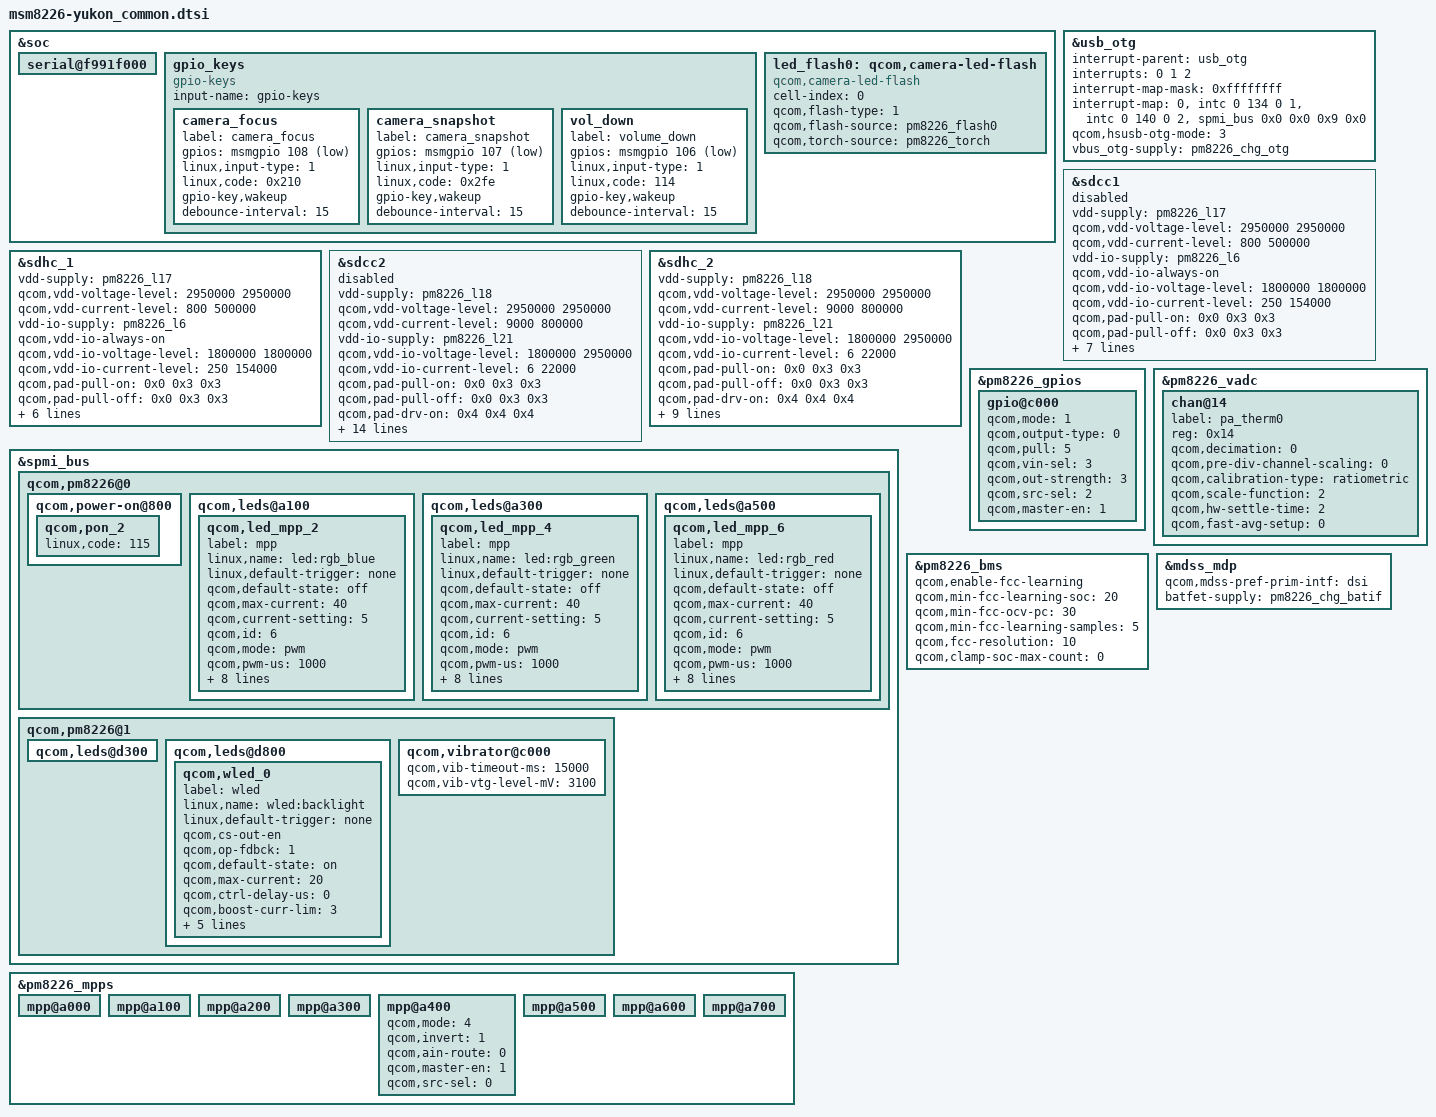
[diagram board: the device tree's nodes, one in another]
/* Copyright (c) 2012-2013, The Linux Foundation. All rights reserved.
 * Copyright (c) 2013 Sony Mobile Communications AB.
 *
 * This program is free software; you can redistribute it and/or modify
 * it under the terms of the GNU General Public License version 2 and
 * only version 2 as published by the Free Software Foundation.
 *
 * This program is distributed in the hope that it will be useful,
 * but WITHOUT ANY WARRANTY; without even the implied warranty of
 * MERCHANTABILITY or FITNESS FOR A PARTICULAR PURPOSE.  See the
 * GNU General Public License for more details.
 */

&soc {
	serial@f991f000 {
		status = "ok";
	};

	gpio_keys {
		compatible = "gpio-keys";
		input-name = "gpio-keys";
		camera_focus {
			label = "camera_focus";
			gpios = <&msmgpio 108 0x1>;
			linux,input-type = <1>;
			linux,code = <0x210>;
			gpio-key,wakeup;
			debounce-interval = <15>;
		};

		camera_snapshot {
			label = "camera_snapshot";
			gpios = <&msmgpio 107 0x1>;
			linux,input-type = <1>;
			linux,code = <0x2fe>;
			gpio-key,wakeup;
			debounce-interval = <15>;
		};

		vol_down {
			label = "volume_down";
			gpios = <&msmgpio 106 0x1>;
			linux,input-type = <1>;
			linux,code = <114>;
			gpio-key,wakeup;
			debounce-interval = <15>;
		};
	};

       led_flash0: qcom,camera-led-flash {
               cell-index = <0>;
               compatible = "qcom,camera-led-flash";
               qcom,flash-type = <1>;
               qcom,flash-source = <&pm8226_flash0>;
               qcom,torch-source = <&pm8226_torch>;
       };

};

&usb_otg {
	#address-cells = <0>;
	interrupt-parent = <&usb_otg>;
	interrupts = <0 1 2>;
	#interrupt-cells = <1>;
	interrupt-map-mask = <0xffffffff>;
	interrupt-map = <0 &intc 0 134 0
			1 &intc 0 140 0
			2 &spmi_bus 0x0 0x0 0x9 0x0>;
	interrupt-names = "core_irq", "async_irq", "pmic_id_irq";

	qcom,hsusb-otg-mode = <3>;
	vbus_otg-supply = <&pm8226_chg_otg>;
};

&sdcc1 {
	vdd-supply = <&pm8226_l17>;
	qcom,vdd-voltage-level = <2950000 2950000>;
	qcom,vdd-current-level = <800 500000>;

	vdd-io-supply = <&pm8226_l6>;
	qcom,vdd-io-always-on;
	qcom,vdd-io-voltage-level = <1800000 1800000>;
	qcom,vdd-io-current-level = <250 154000>;

	qcom,pad-pull-on = <0x0 0x3 0x3>; /* no-pull, pull-up, pull-up */
	qcom,pad-pull-off = <0x0 0x3 0x3>; /* no-pull, pull-up, pull-up */
	qcom,pad-drv-on = <0x4 0x4 0x4>; /* 10mA, 10mA, 10mA */
	qcom,pad-drv-off = <0x0 0x0 0x0>; /* 2mA, 2mA, 2mA */

	qcom,clk-rates = <400000 25000000 50000000 100000000 200000000>;
	qcom,sup-voltages = <2950 2950>;

	qcom,bus-speed-mode = "HS200_1p8v", "DDR_1p8v";
	qcom,nonremovable;

	status = "disabled";
};

&sdhc_1 {
	vdd-supply = <&pm8226_l17>;
	qcom,vdd-voltage-level = <2950000 2950000>;
	qcom,vdd-current-level = <800 500000>;

	vdd-io-supply = <&pm8226_l6>;
	qcom,vdd-io-always-on;
	qcom,vdd-io-voltage-level = <1800000 1800000>;
	qcom,vdd-io-current-level = <250 154000>;

	qcom,pad-pull-on = <0x0 0x3 0x3>; /* no-pull, pull-up, pull-up */
	qcom,pad-pull-off = <0x0 0x3 0x3>; /* no-pull, pull-up, pull-up */
	qcom,pad-drv-on = <0x4 0x4 0x4>; /* 10mA, 10mA, 10mA */
	qcom,pad-drv-off = <0x0 0x0 0x0>; /* 2mA, 2mA, 2mA */

	qcom,clk-rates = <400000 25000000 50000000 100000000 200000000>;
	qcom,bus-speed-mode = "HS200_1p8v", "DDR_1p8v";
	qcom,nonremovable;

	status = "ok";
};

&sdcc2 {
	vdd-supply = <&pm8226_l18>;
	qcom,vdd-voltage-level = <2950000 2950000>;
	qcom,vdd-current-level = <9000 800000>;

	vdd-io-supply = <&pm8226_l21>;
	qcom,vdd-io-voltage-level = <1800000 2950000>;
	qcom,vdd-io-current-level = <6 22000>;

	qcom,pad-pull-on = <0x0 0x3 0x3>; /* no-pull, pull-up, pull-up */
	qcom,pad-pull-off = <0x0 0x3 0x3>; /* no-pull, pull-up, pull-up */
	qcom,pad-drv-on = <0x4 0x4 0x4>; /* 10mA, 10mA, 10mA */
	qcom,pad-drv-off = <0x0 0x0 0x0>; /* 2mA, 2mA, 2mA */

	qcom,clk-rates = <400000 25000000 50000000 100000000 200000000>;
	qcom,sup-voltages = <2950 2950>;

	qcom,xpc;
	qcom,bus-speed-mode = "SDR12", "SDR25", "SDR50", "DDR50", "SDR104";
	qcom,current-limit = <600>; #address-cells = <0>; interrupt-parent = <&sdcc2>;
	interrupts = <0 1 2>;
	#interrupt-cells = <1>;
	interrupt-map-mask = <0xffffffff>;
	interrupt-map = <0 &intc 0 125 0
			1 &intc 0 220 0
			2 &msmgpio 38 0x3>;
	interrupt-names = "core_irq", "bam_irq", "status_irq";
	cd-gpios = <&msmgpio 38 0x1>;

	status = "disabled";
};

&sdhc_2 {
	vdd-supply = <&pm8226_l18>;
	qcom,vdd-voltage-level = <2950000 2950000>;
	qcom,vdd-current-level = <9000 800000>;

	vdd-io-supply = <&pm8226_l21>;
	qcom,vdd-io-voltage-level = <1800000 2950000>;
	qcom,vdd-io-current-level = <6 22000>;

	qcom,pad-pull-on = <0x0 0x3 0x3>; /* no-pull, pull-up, pull-up */
	qcom,pad-pull-off = <0x0 0x3 0x3>; /* no-pull, pull-up, pull-up */
	qcom,pad-drv-on = <0x4 0x4 0x4>; /* 10mA, 10mA, 10mA */
	qcom,pad-drv-off = <0x0 0x0 0x0>; /* 2mA, 2mA, 2mA */

	qcom,clk-rates = <400000 25000000 50000000 100000000 200000000>;

	#address-cells = <0>;
	interrupt-parent = <&sdhc_2>;
	interrupts = <0 1 2>;
	#interrupt-cells = <1>;
	interrupt-map-mask = <0xffffffff>;
	interrupt-map = <0 &intc 0 125 0
			1 &intc 0 221 0
			2 &msmgpio 38 0x3>;
	interrupt-names = "hc_irq", "pwr_irq", "status_irq";
	cd-gpios = <&msmgpio 38 0x1>;

	status = "ok";
};

&spmi_bus {
	qcom,pm8226@0 {
		qcom,power-on@800 {
			qcom,pon_2 {
				linux,code = <115>;
			};
		};

		qcom,leds@a100 {
			status = "okay";
			qcom,led_mpp_2 {
				label = "mpp";
				linux,name = "led:rgb_blue";
				linux,default-trigger = "none";
				qcom,default-state = "off";
				qcom,max-current = <40>;
				qcom,current-setting = <5>;
				qcom,id = <6>;
				qcom,mode = "pwm";
				qcom,pwm-us = <1000>;
				qcom,source-sel = <14>;
				qcom,mode-ctrl = <0x60>;
				qcom,pwm-channel = <3>;
				qcom,start-idx = <1>;
				qcom,ramp-step-ms = <120>;
				qcom,duty-pcts = [00 00 00 00 00
						00 00 00 00 00
						50 00 00 00 00
						00 00 00 00 00
						00];
				qcom,use-blink;
			};
		};

		qcom,leds@a300 {
			status = "okay";
			qcom,led_mpp_4 {
				label = "mpp";
				linux,name = "led:rgb_green";
				linux,default-trigger = "none";
				qcom,default-state = "off";
				qcom,max-current = <40>;
				qcom,current-setting = <5>;
				qcom,id = <6>;
				qcom,mode = "pwm";
				qcom,pwm-us = <1000>;
				qcom,source-sel = <8>;
				qcom,mode-ctrl = <0x60>;
				qcom,pwm-channel = <0>;
				qcom,start-idx = <1>;
				qcom,ramp-step-ms = <120>;
				qcom,duty-pcts = [00 00 00 00 00
						00 00 00 00 00
						50 00 00 00 00
						00 00 00 00 00
						00];
				qcom,use-blink;
			};
		};

		qcom,leds@a500 {
			status = "okay";
			qcom,led_mpp_6 {
				label = "mpp";
				linux,name = "led:rgb_red";
				linux,default-trigger = "none";
				qcom,default-state = "off";
				qcom,max-current = <40>;
				qcom,current-setting = <5>;
				qcom,id = <6>;
				qcom,mode = "pwm";
				qcom,pwm-us = <1000>;
				qcom,mode-ctrl = <0x60>;
				qcom,source-sel = <10>;
				qcom,pwm-channel = <5>;
				qcom,start-idx = <1>;
				qcom,ramp-step-ms = <120>;
				qcom,duty-pcts = [00 00 00 00 00
						00 00 00 00 00
						50 00 00 00 00
						00 00 00 00 00
						00];
				qcom,use-blink;
			};
		};

	};

	qcom,pm8226@1 {
                qcom,leds@d300 {
                        status = "okay";
                };

		qcom,leds@d800 {
			status = "okay";
			qcom,wled_0 {
				label = "wled";
				linux,name = "wled:backlight";
				linux,default-trigger = "none";
				qcom,cs-out-en;
				qcom,op-fdbck = <1>;
				qcom,default-state = "on";
				qcom,max-current = <20>;
				qcom,ctrl-delay-us = <0>;
				qcom,boost-curr-lim = <3>;
				qcom,cp-sel = <0>;
				qcom,switch-freq = <11>;
				qcom,ovp-val = <0>;
				qcom,num-strings = <1>;
				qcom,id = <0>;
			};
		};

		qcom,vibrator@c000 {
			status = "okay";
			qcom,vib-timeout-ms = <15000>;
			qcom,vib-vtg-level-mV = <3100>;
		};
	};
};

&pm8226_gpios {
	/* GPIO_1: PMIC_AUDIO_REF_CLLK*/
	/* Follow QCT */
	gpio@c000 {
		/* XO_PMIC_CDC_MCLK enable for tapan codec */
		qcom,mode = <1>;		/* Digital output */
		qcom,output-type = <0>;		/* CMOS logic */
		qcom,pull = <5>;		/* QPNP_PIN_PULL_NO*/
		qcom,vin-sel = <3>;		/* QPNP_PIN_VIN3 */
		qcom,out-strength = <3>;	/* QPNP_PIN_OUT_STRENGTH_HIGH */
		qcom,src-sel = <2>;		/* QPNP_PIN_SEL_FUNC_1 */
		qcom,master-en = <1>;		/* Enable GPIO */
	};
};

&pm8226_mpps {
	mpp@a000 { /* MPP 1 */
	};

	mpp@a100 { /* MPP 2 */
	};

	mpp@a200 { /* MPP 3 */
	};

	mpp@a300 { /* MPP 4 */
	};

	mpp@a400 { /* MPP 5 */
		/* PA_THERM0 config */
		qcom,mode = <4>; /* AIN input */
		qcom,invert = <1>; /* Enable MPP */
		qcom,ain-route = <0>; /* AMUX 5 */
		qcom,master-en = <1>;
		qcom,src-sel = <0>; /* Function constant */
	};

	mpp@a500 { /* MPP 6 */
	};

	mpp@a600 { /* MPP 7 */
	};

	mpp@a700 { /* MPP 8 */
	};
};

&pm8226_vadc {
	chan@14 {
		label = "pa_therm0";
		reg = <0x14>;
		qcom,decimation = <0>;
		qcom,pre-div-channel-scaling = <0>;
		qcom,calibration-type = "ratiometric";
		qcom,scale-function = <2>;
		qcom,hw-settle-time = <2>;
		qcom,fast-avg-setup = <0>;
	};
};

&pm8226_bms {
	status = "ok";
	qcom,enable-fcc-learning;
	qcom,min-fcc-learning-soc = <20>;
	qcom,min-fcc-ocv-pc = <30>;
	qcom,min-fcc-learning-samples = <5>;
	qcom,fcc-resolution = <10>;

	qcom,clamp-soc-max-count = <0>;
};

&mdss_mdp {
	qcom,mdss-pref-prim-intf = "dsi";
	batfet-supply = <&pm8226_chg_batif>;
};
